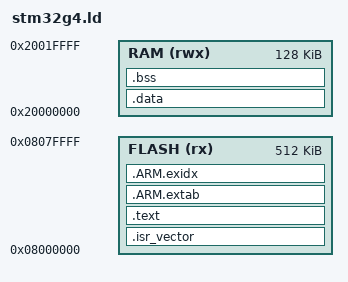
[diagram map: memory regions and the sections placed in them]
/* Memory regions for STM32G474RE: 512KB Flash, 128KB SRAM */
MEMORY
{
  FLASH (rx) : ORIGIN = 0x08000000, LENGTH = 512K
  RAM   (rwx): ORIGIN = 0x20000000, LENGTH = 128K
}

_estack = ORIGIN(RAM) + LENGTH(RAM); /* initial SP from top of RAM */

SECTIONS
{
  .isr_vector :
  {
    KEEP(*(.isr_vector)) /* vector table */
  } > FLASH

  .text :
  {
    *(.text*) *(.rodata*) *(.glue_7) *(.glue_7t)
    KEEP(*(.init)) KEEP(*(.fini))
  } > FLASH

  .ARM.extab : { *(.ARM.extab*) } > FLASH
  .ARM.exidx : { *(.ARM.exidx*) } > FLASH

  .data : AT (ADDR(.text) + SIZEOF(.text))
  {
    _sdata = .;
    *(.data*)
    _edata = .;
  } > RAM

  .bss (NOLOAD) :
  {
    _sbss = .;
    *(.bss*) *(COMMON)
    _ebss = .;
  } > RAM

  PROVIDE(_sidata = LOADADDR(.data));
}

